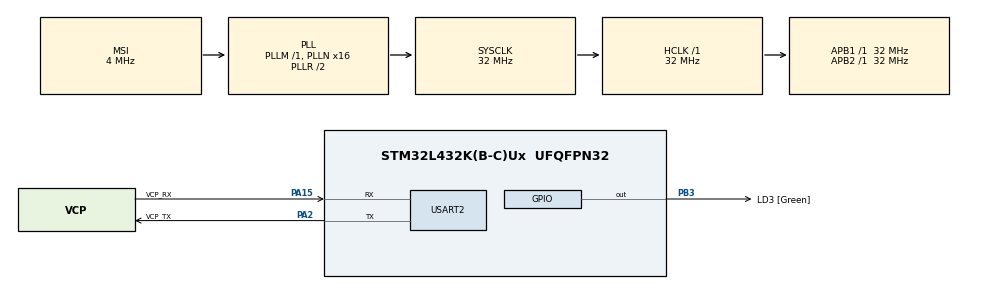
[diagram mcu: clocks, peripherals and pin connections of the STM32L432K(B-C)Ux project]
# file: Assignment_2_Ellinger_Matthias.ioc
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FREERTOS.BinarySemaphores01=SemVal1,Dynamic,NULL,Available;SemVal2,Dynamic,NULL,Available
FREERTOS.Tasks01=OutputTask,24,512,StartOutputTask,Default,NULL,Dynamic,NULL,NULL;ProducerTask1,8,128,StartProducerTask1,Default,NULL,Dynamic,NULL,NULL;ProducerTask2,8,128,StartProducerTask2,Default,NULL,Dynamic,NULL,NULL;ConsumerTask,8,128,StartConsumerTask,Default,NULL,Dynamic,NULL,NULL
FREERTOS.configTOTAL_HEAP_SIZE=5000
FREERTOS.configUSE_NEWLIB_REENTRANT=1
Mcu.Family=STM32L4
Mcu.Name=STM32L432K(B-C)Ux
Mcu.Package=UFQFPN32
NVIC.PriorityGroup=NVIC_PRIORITYGROUP_4
NVIC.TIM6_DAC_IRQn=true\:15\:0\:false\:false\:true\:false\:false\:true\:true
NVIC.TimeBase=TIM6_DAC_IRQn
NVIC.TimeBaseIP=TIM6
PA0.GPIO_Label=MCO [High speed clock in]
PA0.Mode=HSE-External-Clock-Source-for-LittleOrca
PA0.Signal=RCC_CK_IN
PA13\ (JTMS-SWDIO).GPIO_Label=SWDIO
PA13\ (JTMS-SWDIO).Mode=Serial_Wire
PA13\ (JTMS-SWDIO).Signal=SYS_JTMS-SWDIO
PA14\ (JTCK-SWCLK).GPIO_Label=SWCLK
PA14\ (JTCK-SWCLK).Mode=Serial_Wire
PA14\ (JTCK-SWCLK).Signal=SYS_JTCK-SWCLK
PA15\ (JTDI).GPIO_Label=VCP_RX
PA15\ (JTDI).Mode=Asynchronous
PA15\ (JTDI).Signal=USART2_RX
PA2.GPIO_Label=VCP_TX
PA2.Mode=Asynchronous
PA2.Signal=USART2_TX
PB3\ (JTDO-TRACESWO).GPIO_Label=LD3 [Green]
PB3\ (JTDO-TRACESWO).Signal=GPIO_Output
PC14-OSC32_IN\ (PC14).Mode=LSE-External-Oscillator
PC14-OSC32_IN\ (PC14).Signal=RCC_OSC32_IN
PC15-OSC32_OUT\ (PC15).Mode=LSE-External-Oscillator
PC15-OSC32_OUT\ (PC15).Signal=RCC_OSC32_OUT
ProjectManager.HeapSize=0x200
ProjectManager.StackSize=0x400
ProjectManager.TargetToolchain=STM32CubeIDE
RCC.AHBFreq_Value=32000000
RCC.APB1Freq_Value=32000000
RCC.APB1TimFreq_Value=32000000
RCC.APB2Freq_Value=32000000
RCC.APB2TimFreq_Value=32000000
RCC.CortexFreq_Value=32000000
RCC.HCLKFreq_Value=32000000
RCC.HSE_VALUE=8000000
RCC.HSI16_VALUE=16000000
RCC.HSI48_VALUE=48000000
RCC.HSI_VALUE=16000000
RCC.MSI_VALUE=4000000
RCC.PLLMUL=RCC_PLLMUL_4
RCC.PLLN=16
RCC.SYSCLKFreq_VALUE=32000000
RCC.SYSCLKSource=RCC_SYSCLKSOURCE_PLLCLK
RCC.VCOOutputFreq_Value=64000000
USART2.VirtualMode-Asynchronous=VM_ASYNC
VP_FREERTOS_VS_CMSIS_V2.Mode=CMSIS_V2
VP_SYS_VS_tim6.Mode=TIM6
board=NUCLEO-L432KC

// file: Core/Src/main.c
/* USER CODE BEGIN Header */
/**
  ******************************************************************************
  * @file           : main.c
  * @brief          : Main program body
  ******************************************************************************
  * @attention
  *
  * Copyright (c) 2026 STMicroelectronics.
  * All rights reserved.
  *
  * This software is licensed under terms that can be found in the LICENSE file
  * in the root directory of this software component.
  * If no LICENSE file comes with this software, it is provided AS-IS.
  *
  ******************************************************************************
  */
/* USER CODE END Header */
#include "main.h"
#include "cmsis_os.h"

/* USER CODE BEGIN Includes */
#include "output.h"
#include "semphr.h"
/* USER CODE END Includes */

/* USER CODE BEGIN PD */

#define PROTECTED

/* USER CODE END PD */

UART_HandleTypeDef huart2;

/* Definitions for OutputTask */
osThreadId_t OutputTaskHandle;
const osThreadAttr_t OutputTask_attributes = {
  .name = "OutputTask",
  .stack_size = 512 * 4,
  .priority = (osPriority_t) osPriorityNormal,
};
/* Definitions for ProducerTask1 */
osThreadId_t ProducerTask1Handle;
const osThreadAttr_t ProducerTask1_attributes = {
  .name = "ProducerTask1",
  .stack_size = 128 * 4,
  .priority = (osPriority_t) osPriorityLow,
};
/* Definitions for ProducerTask2 */
osThreadId_t ProducerTask2Handle;
const osThreadAttr_t ProducerTask2_attributes = {
  .name = "ProducerTask2",
  .stack_size = 128 * 4,
  .priority = (osPriority_t) osPriorityLow,
};
/* Definitions for ConsumerTask */
osThreadId_t ConsumerTaskHandle;
const osThreadAttr_t ConsumerTask_attributes = {
  .name = "ConsumerTask",
  .stack_size = 128 * 4,
  .priority = (osPriority_t) osPriorityLow,
};
/* Definitions for SemVal1 */
osSemaphoreId_t SemVal1Handle;
const osSemaphoreAttr_t SemVal1_attributes = {
  .name = "SemVal1"
};
/* Definitions for SemVal2 */
osSemaphoreId_t SemVal2Handle;
const osSemaphoreAttr_t SemVal2_attributes = {
  .name = "SemVal2"
};
/* USER CODE BEGIN PV */
_data* data;
/* USER CODE END PV */

void SystemClock_Config(void);
static void MX_GPIO_Init(void);
static void MX_USART2_UART_Init(void);
void StartOutputTask(void *argument);
void StartProducerTask1(void *argument);
void StartProducerTask2(void *argument);
void StartConsumerTask(void *argument);

int main(void)
{

  /* MCU Configuration--------------------------------------------------------*/

  /* Reset of all peripherals, Initializes the Flash interface and the Systick. */
  HAL_Init();

  /* Configure the system clock */
  SystemClock_Config();

  /* Initialize all configured peripherals */
  MX_GPIO_Init();
  MX_USART2_UART_Init();
  /* USER CODE BEGIN 2 */
  data = pvPortMalloc(sizeof(_data));
  data ->val_p1 = 0;
  sprintf(data ->str_p1,"This is a test message to show the importance of task synchronisation. The current value of sensor 1 reads 0");
  data ->val_p2 = 0;
  sprintf(data ->str_p2,"This message belongs to aircraft Airbus A350 flight number GFIK42. The current value of sensor 2 reads 0");
  /* USER CODE END 2 */

  /* Init scheduler */
  osKernelInitialize();

  /* Create the semaphores(s) */
  /* creation of SemVal1 */
  SemVal1Handle = osSemaphoreNew(1, 1, &SemVal1_attributes);

  /* creation of SemVal2 */
  SemVal2Handle = osSemaphoreNew(1, 1, &SemVal2_attributes);

  /* Create the thread(s) */
  /* creation of OutputTask */
  OutputTaskHandle = osThreadNew(StartOutputTask, NULL, &OutputTask_attributes);

  /* creation of ProducerTask1 */
  ProducerTask1Handle = osThreadNew(StartProducerTask1, NULL, &ProducerTask1_attributes);

  /* creation of ProducerTask2 */
  ProducerTask2Handle = osThreadNew(StartProducerTask2, NULL, &ProducerTask2_attributes);

  /* creation of ConsumerTask */
  ConsumerTaskHandle = osThreadNew(StartConsumerTask, NULL, &ConsumerTask_attributes);

  /* Start scheduler */
  osKernelStart();

  /* We should never get here as control is now taken by the scheduler */

  /* Infinite loop */
  while (1)
  {

  }
}

void SystemClock_Config(void)
{
  RCC_OscInitTypeDef RCC_OscInitStruct = {0};
  RCC_ClkInitTypeDef RCC_ClkInitStruct = {0};

  /** Configure the main internal regulator output voltage
  */
  if (HAL_PWREx_ControlVoltageScaling(PWR_REGULATOR_VOLTAGE_SCALE1) != HAL_OK)
  {
    Error_Handler();
  }

  /** Configure LSE Drive Capability
  */
  HAL_PWR_EnableBkUpAccess();
  __HAL_RCC_LSEDRIVE_CONFIG(RCC_LSEDRIVE_LOW);

  /** Initializes the RCC Oscillators according to the specified parameters
  * in the RCC_OscInitTypeDef structure.
  */
  RCC_OscInitStruct.OscillatorType = RCC_OSCILLATORTYPE_LSE|RCC_OSCILLATORTYPE_MSI;
  RCC_OscInitStruct.LSEState = RCC_LSE_ON;
  RCC_OscInitStruct.MSIState = RCC_MSI_ON;
  RCC_OscInitStruct.MSICalibrationValue = 0;
  RCC_OscInitStruct.MSIClockRange = RCC_MSIRANGE_6;
  RCC_OscInitStruct.PLL.PLLState = RCC_PLL_ON;
  RCC_OscInitStruct.PLL.PLLSource = RCC_PLLSOURCE_MSI;
  RCC_OscInitStruct.PLL.PLLM = 1;
  RCC_OscInitStruct.PLL.PLLN = 16;
  RCC_OscInitStruct.PLL.PLLP = RCC_PLLP_DIV7;
  RCC_OscInitStruct.PLL.PLLQ = RCC_PLLQ_DIV2;
  RCC_OscInitStruct.PLL.PLLR = RCC_PLLR_DIV2;
  if (HAL_RCC_OscConfig(&RCC_OscInitStruct) != HAL_OK)
  {
    Error_Handler();
  }

  /** Initializes the CPU, AHB and APB buses clocks
  */
  RCC_ClkInitStruct.ClockType = RCC_CLOCKTYPE_HCLK|RCC_CLOCKTYPE_SYSCLK
                              |RCC_CLOCKTYPE_PCLK1|RCC_CLOCKTYPE_PCLK2;
  RCC_ClkInitStruct.SYSCLKSource = RCC_SYSCLKSOURCE_PLLCLK;
  RCC_ClkInitStruct.AHBCLKDivider = RCC_SYSCLK_DIV1;
  RCC_ClkInitStruct.APB1CLKDivider = RCC_HCLK_DIV1;
  RCC_ClkInitStruct.APB2CLKDivider = RCC_HCLK_DIV1;

  if (HAL_RCC_ClockConfig(&RCC_ClkInitStruct, FLASH_LATENCY_1) != HAL_OK)
  {
    Error_Handler();
  }

  /** Enable MSI Auto calibration
  */
  HAL_RCCEx_EnableMSIPLLMode();
}

static void MX_USART2_UART_Init(void)
{

  huart2.Instance = USART2;
  huart2.Init.BaudRate = 115200;
  huart2.Init.WordLength = UART_WORDLENGTH_8B;
  huart2.Init.StopBits = UART_STOPBITS_1;
  huart2.Init.Parity = UART_PARITY_NONE;
  huart2.Init.Mode = UART_MODE_TX_RX;
  huart2.Init.HwFlowCtl = UART_HWCONTROL_NONE;
  huart2.Init.OverSampling = UART_OVERSAMPLING_16;
  huart2.Init.OneBitSampling = UART_ONE_BIT_SAMPLE_DISABLE;
  huart2.AdvancedInit.AdvFeatureInit = UART_ADVFEATURE_NO_INIT;
  if (HAL_UART_Init(&huart2) != HAL_OK)
  {
    Error_Handler();
  }

}

static void MX_GPIO_Init(void)
{
  GPIO_InitTypeDef GPIO_InitStruct = {0};

  /* GPIO Ports Clock Enable */
  __HAL_RCC_GPIOC_CLK_ENABLE();
  __HAL_RCC_GPIOA_CLK_ENABLE();
  __HAL_RCC_GPIOB_CLK_ENABLE();

  /*Configure GPIO pin Output Level */
  HAL_GPIO_WritePin(LD3_GPIO_Port, LD3_Pin, GPIO_PIN_RESET);

  /*Configure GPIO pin : LD3_Pin */
  GPIO_InitStruct.Pin = LD3_Pin;
  GPIO_InitStruct.Mode = GPIO_MODE_OUTPUT_PP;
  GPIO_InitStruct.Pull = GPIO_NOPULL;
  GPIO_InitStruct.Speed = GPIO_SPEED_FREQ_LOW;
  HAL_GPIO_Init(LD3_GPIO_Port, &GPIO_InitStruct);

}

void StartOutputTask(void *argument)
{
  /* USER CODE BEGIN 5 */
  /* Infinite loop */
  for(;;)
  {
	#ifdef PROTECTED
		xSemaphoreTake(SemVal1Handle,100);
		xSemaphoreTake(SemVal2Handle,100);
		output_data(data,huart2);
		xSemaphoreGive(SemVal2Handle);
		xSemaphoreGive(SemVal1Handle);
		osDelay(500);
	#endif

	#ifndef PROTECTED
		output_data(data,huart2);
		osDelay(500);
	#endif

  }
  osThreadTerminate(NULL);
  /* USER CODE END 5 */
}

void StartProducerTask1(void *argument)
{
  /* USER CODE BEGIN StartProducerTask1 */
  /* Infinite loop */
  for(;;)
  {
	#ifdef PROTECTED
		xSemaphoreTake(SemVal1Handle,100);
		data->val_p1 +=1;
		xSemaphoreGive(SemVal1Handle);
		osDelay(300);
	#endif

	#ifndef PROTECTED
		data->val_p1 +=1;
		osDelay(300);
	#endif

  }
  osThreadTerminate(NULL);
  /* USER CODE END StartProducerTask1 */
}

void StartProducerTask2(void *argument)
{
  /* USER CODE BEGIN StartProducerTask2 */
  /* Infinite loop */
  for(;;)
  {
	#ifdef PROTECTED
		xSemaphoreTake(SemVal2Handle,100);
		data->val_p2 +=1;
		xSemaphoreGive(SemVal2Handle);
		osDelay(500);
	#endif

	#ifndef PROTECTED
		data->val_p2 +=1;
		osDelay(500);
	#endif
  }
  osThreadTerminate(NULL);
  /* USER CODE END StartProducerTask2 */
}

void StartConsumerTask(void *argument)
{
  /* USER CODE BEGIN StartConsumerTask */
  /* Infinite loop */
  for(;;)
  {
	#ifdef PROTECTED
		xSemaphoreTake(SemVal1Handle,100);
		if(data->val_p1%2 == 0)
		{
			osDelay(100);
			sprintf(data->str_p1, "This is a test message to show the importance of task synchronisation. The current value of sensor 1 reads %d.%d",data->val_p1/2,(data->val_p1%2)*5);
		}
		xSemaphoreGive(SemVal1Handle);
		xSemaphoreTake(SemVal2Handle,100);
		if(data->val_p2%2 == 0)
		{
			osDelay(100);
			sprintf(data->str_p2, "This message belongs to aircraft Airbus A350 flight number GFIK42. The current value of sensor 2 reads  %d.%d",data->val_p2/2, (data->val_p2%2)*5 );
		}
		xSemaphoreGive(SemVal2Handle);
		osDelay(100);
	#endif

	#ifndef PROTECTED
		if(data->val_p1%2 == 0)
				{
					osDelay(100);
					sprintf(data->str_p1, "This is a test message to show the importance of task synchronisation. The current value of sensor 1 reads %d.%d",data->val_p1/2,(data->val_p1%2)*5);
				}
		if(data->val_p2%2 == 0)
				{
					osDelay(100);
					sprintf(data->str_p2, "This message belongs to aircraft Airbus A350 flight number GFIK42. The current value of sensor 2 reads  %d.%d",data->val_p2/2, (data->val_p2%2)*5 );
				}
		osDelay(100);
	#endif

  }
  osThreadTerminate(NULL);
  /* USER CODE END StartConsumerTask */
}

void HAL_TIM_PeriodElapsedCallback(TIM_HandleTypeDef *htim)
{
  if (htim->Instance == TIM6)
  {
    HAL_IncTick();
  }
}

void Error_Handler(void)
{
  __disable_irq();
  while (1)
  {
  }
}
